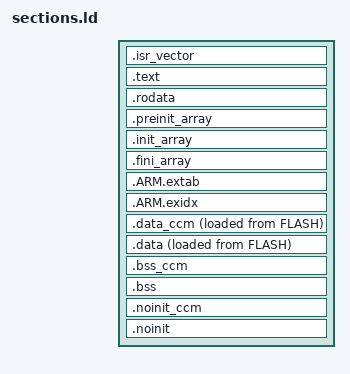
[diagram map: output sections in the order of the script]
/*
 * SuperTinyKernel(TM) RTOS: Lightweight High-Performance Deterministic C++ RTOS for Embedded Systems.
 *
 * Source: https://github.com/SuperTinyKernel-RTOS
 *
 * Copyright (c) 2022-2026 Neutron Code Limited <stk@neutroncode.com>. All Rights Reserved.
 * License: MIT License, see LICENSE for a full text.
 */

/*! \file  sections.ld
    \brief Sections of the STK STM32Fx target (Cortex-M0/M3/M4), common for all families.
    \note  Used together with the memory map of the family: <tt>-T mem.ld -T sections.ld</tt>, which defines the
           regions \c FLASH, \c RAM and \c CCMRAM (zero length if the device has no CCM RAM).

    \par Memory layout
     - \c FLASH  - vector table, code, read-only data, load images of the initialized data.
     - \c RAM    - .data, .bss, .noinit, then the heap which grows up, the main stack at the top grows down.
     - \c CCMRAM - data placed with the \c .data.CCMRAM / \c .bss.CCMRAM / \c .noinit.CCMRAM sections (STM32F4). The CPU
                   accesses it without wait states, DMA can not.

    \par Build-time options
    \note  Sizes are in bytes and are overridden with \c --defsym, see the warning in mem.ld about the option order:
           \code
           -Xlinker --defsym=__stack_size=0x2000   // main stack, multiple of 8 (default 0x400)
           \endcode
           The main stack is used by the exceptions/interrupts and, until the kernel switches to the task stacks,
           by the start-up code and main().

    \par Symbols consumed by the code
     - \c _estack, \c __stack                         - top of the main stack (initial MSP, vectors_xxx.c).
     - \c __vectors_start                             - vector table (hardware.c sets VTOR).
     - \c _sidata, \c _sdata, \c _edata, \c _sbss, \c _ebss, and the same with the \c _ccm suffix (startup.c).
     - \c __preinit_array_xxx, \c __init_array_xxx, \c __fini_array_xxx (startup.c).
     - \c __heap_start, \c __heap_end                 - heap (system.c); \c end / \c _end are the C library names.
    \see mem.ld, startup.c, system.c
*/

ENTRY(Reset_Handler)

/* Require the linker to resolve __isr_vectors at link time so vectors_stm32xxx.o
 * is pulled in from the static library when the vector table lives in an archive. */
EXTERN(__isr_vectors)

/* build-time option (internal symbol, see mem.ld) */
__stk_stack_size = DEFINED(__stack_size) ? __stack_size : 0x400;

/* the main stack takes the top of RAM */
_estack = ORIGIN(RAM) + LENGTH(RAM);
__stack = _estack;
__stack_limit = _estack - __stk_stack_size;

SECTIONS
{
    /*! \brief Vector table: must be the first thing in flash. */
    .isr_vector : ALIGN(4)
    {
        __vectors_start = .;
        KEEP(*(.isr_vector))
    } >FLASH

    /*! \brief Code. */
    .text : ALIGN(4)
    {
        *(.text .text.*)
        *(.glue_7)          /* ARM -> Thumb veneers, always generated by the linker */
        *(.glue_7t)         /* Thumb -> ARM veneers */
        *(vtable)           /* C++ virtual tables */
        KEEP(*(.eh_frame*))
    } >FLASH

    /*! \brief Read-only data. */
    .rodata : ALIGN(4)
    {
        *(.rodata .rodata.* .constdata .constdata.*)
        . = ALIGN(4);
    } >FLASH

    /*! \brief Arrays of static constructors / destructors, see startup.c. */
    .preinit_array : ALIGN(4)
    {
        PROVIDE_HIDDEN(__preinit_array_start = .);
        KEEP(*(.preinit_array .preinit_array.*))
        PROVIDE_HIDDEN(__preinit_array_end = .);
    } >FLASH

    .init_array : ALIGN(4)
    {
        PROVIDE_HIDDEN(__init_array_start = .);
        KEEP(*(SORT(.init_array.*)))
        KEEP(*(.init_array))
        PROVIDE_HIDDEN(__init_array_end = .);
    } >FLASH

    .fini_array : ALIGN(4)
    {
        PROVIDE_HIDDEN(__fini_array_start = .);
        KEEP(*(SORT(.fini_array.*)))
        KEEP(*(.fini_array))
        PROVIDE_HIDDEN(__fini_array_end = .);
    } >FLASH

    /*! \brief C++ exception unwinding tables. */
    .ARM.extab : ALIGN(4)
    {
        *(.ARM.extab* .gnu.linkonce.armextab.*)
    } >FLASH

    .ARM.exidx : ALIGN(4)
    {
        __exidx_start = .;
        *(.ARM.exidx* .gnu.linkonce.armexidx.*)
        __exidx_end = .;
    } >FLASH

    . = ALIGN(4);
    _etext = .;
    __etext = .;

    /*! \brief Initialized data of CCM RAM, the image is in flash. */
    _sidata_ccm = LOADADDR(.data_ccm);

    .data_ccm : ALIGN(4)
    {
        _sdata_ccm = .;
        *(.data.CCMRAM .data.CCMRAM.*)
        . = ALIGN(4);
        _edata_ccm = .;
    } >CCMRAM AT>FLASH

    /*! \brief Initialized data, the image is in flash. */
    _sidata = LOADADDR(.data);

    .data : ALIGN(4)
    {
        _sdata = .;
        *(.data .data.*)
        *(.gnu.linkonce.d.*)
        . = ALIGN(4);
        _edata = .;
    } >RAM AT>FLASH

    /*! \brief Zero-initialized data. NOLOAD: the sections hold no image. */
    .bss_ccm (NOLOAD) : ALIGN(4)
    {
        _sbss_ccm = .;
        *(.bss.CCMRAM .bss.CCMRAM.*)
        . = ALIGN(4);
        _ebss_ccm = .;
    } >CCMRAM

    .bss (NOLOAD) : ALIGN(4)
    {
        _sbss = .;
        *(.bss .bss.*)
        *(COMMON)
        . = ALIGN(4);
        _ebss = .;
    } >RAM

    /*! \brief Data which survives the start-up: neither initialized nor zeroed. */
    .noinit_ccm (NOLOAD) : ALIGN(4)
    {
        *(.noinit.CCMRAM .noinit.CCMRAM.*)
    } >CCMRAM

    .noinit (NOLOAD) : ALIGN(8)
    {
        *(.noinit .noinit.*)
        . = ALIGN(8);
    } >RAM

    /*! \brief Heap: everything between the static data and the main stack, the symbols are used by _sbrk(). */
    __heap_start = ALIGN(8);
    PROVIDE(end = __heap_start);
    PROVIDE(_end = __heap_start);
    PROVIDE(__end__ = __heap_start);
    __heap_end = __stack_limit;

    /*! \brief Link-time check only, no memory is allocated here. */
    ASSERT(__stk_stack_size % 8 == 0, "STK: __stack_size must be a multiple of 8")
    ASSERT(__heap_start <= __heap_end, "STK: .data/.bss and the main stack do not fit into RAM")

    /DISCARD/ :
    {
        *(.note.GNU-stack)
    }
}
